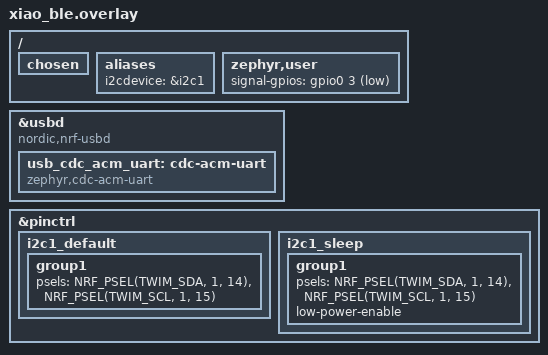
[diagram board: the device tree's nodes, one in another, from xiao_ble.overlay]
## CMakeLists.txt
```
# SPDX-License-Identifier: Apache-2.0

cmake_minimum_required(VERSION 3.20.0)
find_package(Zephyr REQUIRED HINTS $ENV{ZEPHYR_BASE})
project(peripheral)

FILE(GLOB app_sources src/*.c)
target_sources(app PRIVATE ${app_sources})
```

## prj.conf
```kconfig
# Increased stack due to settings API usage
CONFIG_SYSTEM_WORKQUEUE_STACK_SIZE=2048
CONFIG_HEAP_MEM_POOL_SIZE=2048

CONFIG_BOOT_DELAY=5000
CONFIG_BT=y

CONFIG_BT_SMP=y
CONFIG_BT_SIGNING=y
CONFIG_BT_PERIPHERAL=y
CONFIG_BT_DIS=y
CONFIG_BT_ATT_PREPARE_COUNT=5
CONFIG_BT_PRIVACY=y
CONFIG_BT_DEVICE_NAME="PPG Sensor UU"
CONFIG_BT_DEVICE_APPEARANCE=3137
CONFIG_BT_DEVICE_NAME_DYNAMIC=y
CONFIG_BT_DEVICE_NAME_MAX=65


CONFIG_BT_KEYS_OVERWRITE_OLDEST=y
CONFIG_BT_SETTINGS=y
CONFIG_FLASH=y
CONFIG_FLASH_PAGE_LAYOUT=y
CONFIG_FLASH_MAP=y
CONFIG_NVS=y
CONFIG_SETTINGS=y
CONFIG_I2C=y
CONFIG_EVENTS=y
```

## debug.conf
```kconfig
CONFIG_BT_DEBUG_LOG=y
CONFIG_PRINTK=y
CONFIG_ASSERT=y
CONFIG_LOG_DEFAULT_LEVEL=4
CONFIG_LOG=y


#CONFIG_BOOT_DELAY=5000
```

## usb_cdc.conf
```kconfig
CONFIG_STDOUT_CONSOLE=y
CONFIG_SERIAL=y
CONFIG_CONSOLE=y
CONFIG_USB_DEVICE_STACK=y
CONFIG_USB_DEVICE_PRODUCT="ppg_sensor"
CONFIG_UART_CONSOLE=y
CONFIG_UART_LINE_CTRL=y
CONFIG_UART_INTERRUPT_DRIVEN=y
CONFIG_USB_DEVICE_VID=0x0403
CONFIG_USB_DEVICE_PID=0x6001
```

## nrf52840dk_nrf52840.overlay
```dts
/ {
    chosen {
        // zephyr,console = &usb_cdc_acm_uart;
        // zephyr,shell-uart = &usb_cdc_acm_uart;
    };
	aliases {
		i2cdevice = &i2c0;
	};
	zephyr,user {
        signal-gpios = <&gpio0 27 (GPIO_PULL_UP | GPIO_ACTIVE_LOW)>;
    };
};


// zephyr_udc0: &usbd {
// 	compatible = "nordic,nrf-usbd";
// 	status = "okay";

// 	usb_cdc_acm_uart: cdc-acm-uart {
// 		compatible = "zephyr,cdc-acm-uart";
// 	};
// };

&pinctrl {
	i2c0_default: i2c0_default {
		group1 {
			psels = <NRF_PSEL(TWIM_SDA, 0,29)>,
				<NRF_PSEL(TWIM_SCL, 0, 31)>;
		};
	};

	i2c0_sleep: i2c0_sleep {
		group1 {
			psels = <NRF_PSEL(TWIM_SDA, 0, 29)>,
				<NRF_PSEL(TWIM_SCL, 0, 31)>;
			low-power-enable;
		};
	};
};
```

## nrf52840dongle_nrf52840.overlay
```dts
/ {
    chosen {
      //  zephyr,console = &usb_cdc_acm_uart;
      //  zephyr,shell-uart = &usb_cdc_acm_uart;
    };
    zephyr,user {
        signal-gpios = <&gpio0 20 (GPIO_PULL_UP | GPIO_ACTIVE_LOW)>;
    };
};


/* zephyr_udc0: &usbd {
	compatible = "nordic,nrf-usbd";
	status = "okay";

	usb_cdc_acm_uart: cdc-acm-uart {
		compatible = "zephyr,cdc-acm-uart";
	};
}; */



&pinctrl {
	i2c0_default: i2c0_default {
		group1 {
			psels = <NRF_PSEL(TWIM_SDA, 0,29)>,
				<NRF_PSEL(TWIM_SCL, 0, 31)>;
		};
	};

	i2c0_sleep: i2c0_sleep {
		group1 {
			psels = <NRF_PSEL(TWIM_SDA, 0, 29)>,
				<NRF_PSEL(TWIM_SCL, 0, 31)>;
			low-power-enable;
		};
	};
};
```

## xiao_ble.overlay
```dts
/ {
    chosen {
        //zephyr,console = &usb_cdc_acm_uart;
        //zephyr,shell-uart = &usb_cdc_acm_uart;
    };
	aliases {
		i2cdevice = &i2c1;
	};
    zephyr,user {
        signal-gpios = <&gpio0 3 (GPIO_PULL_UP | GPIO_ACTIVE_LOW)>;
    };
};

zephyr_udc0: &usbd {
	compatible = "nordic,nrf-usbd";
	status = "okay";

	usb_cdc_acm_uart: cdc-acm-uart {
		compatible = "zephyr,cdc-acm-uart";
	};
};

&pinctrl {
	i2c1_default: i2c1_default {
		group1 {
			psels = <NRF_PSEL(TWIM_SDA, 1, 14)>,
				<NRF_PSEL(TWIM_SCL, 1, 15)>;
		};
	};

	i2c1_sleep: i2c1_sleep {
		group1 {
			psels = <NRF_PSEL(TWIM_SDA, 1, 14)>,
				<NRF_PSEL(TWIM_SCL, 1, 15)>;
			low-power-enable;
		};
	};
};
```

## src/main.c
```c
/* main.c - Application main entry point */

/*
 * Copyright (c) 2015-2016 Intel Corporation
 *
 * SPDX-License-Identifier: Apache-2.0
 */
#include "main.h"
#include <zephyr/types.h>
#include <stddef.h>
#include <string.h>
#include <errno.h>

#include <zephyr/sys/byteorder.h>
#include <zephyr/kernel.h>

#include <zephyr/logging/log.h>


#include <zephyr/settings/settings.h>

//#include <zephyr/usb/usb_device.h>

//#include <zephyr/drivers/uart.h>


#include <zephyr/bluetooth/bluetooth.h>
#include <zephyr/bluetooth/hci.h>
#include <zephyr/bluetooth/conn.h>
#include <zephyr/bluetooth/uuid.h>
#include <zephyr/bluetooth/gatt.h>
#include <zephyr/drivers/gpio.h>
#include <zephyr/bluetooth/services/hrs.h>


LOG_MODULE_REGISTER(ppgmain);

//#include "cts.h"

//Pulse Oximeter service 0x1822
#define BT_UUID_POS_VAL 0x1822
#define BT_UUID_POS BT_UUID_DECLARE_16(BT_UUID_POS_VAL)

//0x2A5F PLX Continuous Measurement
//#define BT_UUID_PLX_MEASUREMENT_VAL 0x2A5F
//#define BT_UUID_PLX_MEASUREMENT BT_UUID_DECLARE_16(BT_UUID_PLX_MEASUREMENT_VAL)

//Fingertip Pulse Oximeter 0x0C41
#define BT_UUID_FINGERTIP_PO_MEASUREMENT_VAL 0x0C41
#define BT_UUID_FINGERTIP_PO_MEASUREMENT BT_UUID_DECLARE_16(BT_UUID_FINGERTIP_PO_MEASUREMENT_VAL)


#define ZEPHYR_USER_NODE DT_PATH(zephyr_user)

volatile bool notify_enable = 0;

K_EVENT_DEFINE(notify_event);

static void vnd_ccc_cfg_changed(const struct bt_gatt_attr *attr, uint16_t value)
{
	ARG_UNUSED(attr);
	notify_enable = (value == BT_GATT_CCC_NOTIFY);
	LOG_INF("value %i", value);
	k_event_post(&notify_event, (value ? evt_powerup : evt_powerdown));
}

BT_GATT_SERVICE_DEFINE(ppg_svc,
	BT_GATT_PRIMARY_SERVICE(BT_UUID_POS),	
		BT_GATT_CHARACTERISTIC(BT_UUID_FINGERTIP_PO_MEASUREMENT,
					BT_GATT_CHRC_READ | BT_GATT_CHRC_WRITE |
			        BT_GATT_CHRC_NOTIFY, 
					BT_GATT_PERM_READ | BT_GATT_PERM_WRITE, NULL, NULL, NULL),
			BT_GATT_CCC(vnd_ccc_cfg_changed,
					BT_GATT_PERM_READ | BT_GATT_PERM_WRITE),				
);


static const struct bt_data ad[] = {
	BT_DATA_BYTES(BT_DATA_FLAGS, (BT_LE_AD_GENERAL | BT_LE_AD_NO_BREDR)),
	BT_DATA_BYTES(BT_DATA_UUID16_ALL,
			   BT_UUID_16_ENCODE(BT_UUID_POS_VAL),
		      	BT_UUID_16_ENCODE(BT_UUID_BAS_VAL),
			  ),	
};

K_SEM_DEFINE(sem_initialized_max30102, 0, 1);
K_SEM_DEFINE(sem_interruptmax30102, 0, 1);
K_FIFO_DEFINE(ppg_items);

static struct gpio_callback interrupt_max30102;
static const struct gpio_dt_spec signal = GPIO_DT_SPEC_GET(ZEPHYR_USER_NODE, signal_gpios);





void mtu_updated(struct bt_conn *conn, uint16_t tx, uint16_t rx)
{
	LOG_DBG("Updated MTU: TX: %d RX: %d bytes\n", tx, rx);
}

static struct bt_gatt_cb gatt_callbacks = {
	.att_mtu_updated = mtu_updated
};

static void connected(struct bt_conn *conn, uint8_t err)
{
	if (err) {
		LOG_ERR("Connection failed (err 0x%02x)\n", err);
	} else {
		LOG_INF("Connected\n");		
	}
}

static void disconnected(struct bt_conn *conn, uint8_t reason)
{
	LOG_INF("Disconnected (reason 0x%02x)\n", reason);	
}

BT_CONN_CB_DEFINE(conn_callbacks) = {
	.connected = connected,
	.disconnected = disconnected,	
};


static void bt_ready(void)
{
	int err;

	LOG_DBG("Bluetooth initialized\n");
	

	if (IS_ENABLED(CONFIG_SETTINGS)) {
		settings_load();
	}

	err = bt_le_adv_start(BT_LE_ADV_CONN_NAME, ad, ARRAY_SIZE(ad), NULL, 0);
	if (err) {
		LOG_ERR("Advertising failed to start (err %d)\n", err);
		return;
	}

	LOG_DBG("Advertising successfully started\n");
}

static void auth_passkey_display(struct bt_conn *conn, unsigned int passkey)
{
	char addr[BT_ADDR_LE_STR_LEN];

	bt_addr_le_to_str(bt_conn_get_dst(conn), addr, sizeof(addr));

	printk("Passkey for %s: %06u\n", addr, passkey);
}

static void auth_cancel(struct bt_conn *conn)
{
	char addr[BT_ADDR_LE_STR_LEN];

	bt_addr_le_to_str(bt_conn_get_dst(conn), addr, sizeof(addr));

	LOG_INF("Pairing cancelled: %s\n", addr);
}

static struct bt_conn_auth_cb auth_cb_display = {
	.passkey_display = auth_passkey_display,
	.passkey_entry = NULL,
	.cancel = auth_cancel,
	
};


void max30102isr(const struct device *dev, struct gpio_callback *cb, uint32_t pins) {	
	k_sem_give(&sem_interruptmax30102);			
}

void attachinterrupt(void) {
	
	__ASSERT(device_is_ready(signal.port), "custom device not ready");
	gpio_pin_configure_dt(&signal, GPIO_INPUT);
	gpio_pin_interrupt_configure_dt(&signal, GPIO_INT_EDGE_TO_ACTIVE);
	gpio_init_callback(&interrupt_max30102, max30102isr, BIT(signal.pin));
	gpio_add_callback(signal.port, &interrupt_max30102);	
	LOG_INF("attached");
}



void main(void)
{


// #if DT_NODE_HAS_COMPAT(DT_CHOSEN(zephyr_shell_uart), zephyr_cdc_acm_uart)
// 	const struct device *dev;
// 	uint32_t dtr = 0;

// 	dev = DEVICE_DT_GET(DT_CHOSEN(zephyr_shell_uart));
// 	if (!device_is_ready(dev) || usb_enable(NULL)) {
// 		return;
// 	}

// 	while (!dtr) {
// 		uart_line_ctrl_get(dev, UART_LINE_CTRL_DTR, &dtr);
// 		k_sleep(K_MSEC(100));
// 	}
// #endif	



	struct bt_gatt_attr *vnd_ind_attr;
	char str[BT_UUID_STR_LEN];
	int err;
	LOG_INF("enabling bt");
	err = bt_enable(NULL);
	if (err) {
		LOG_ERR("Bluetooth init failed (err %d)\n", err);
		return;
	}
	LOG_INF("bt enabled");

	bt_ready();

	bt_gatt_cb_register(&gatt_callbacks);
	bt_conn_auth_cb_register(&auth_cb_display);
	
	static struct bt_uuid_16 vnd_enc_uuid = BT_UUID_INIT_16(BT_UUID_FINGERTIP_PO_MEASUREMENT_VAL);
	vnd_ind_attr = bt_gatt_find_by_uuid(ppg_svc.attrs, ppg_svc.attr_count,
					    &vnd_enc_uuid.uuid);
						

	//bt_uuid_to_str(&vnd_enc_uuid.uuid, str, sizeof(str));
	bt_uuid_to_str(BT_UUID_POS, str, sizeof(str));
	LOG_DBG("Indicate VND attr %p (UUID %s)\n", vnd_ind_attr, str);	
	
	if(max30102_init()) {
		LOG_ERR("could not initialize");
		k_sleep(K_FOREVER);		
	}		
	attachinterrupt();	
	uint8_t max_read_state = max30102_interrupt_state(); //clear interrupt;
	LOG_DBG("max initialized, read state:%i", max_read_state);	
	k_sem_give(&sem_initialized_max30102);			
	shutdown();


	fifo_item_t *queued;
	for(;;) {
		
		queued = k_fifo_get(&ppg_items, K_FOREVER);	
		uint32_t test = 42;
		if (notify_enable) {			
			
			err = bt_gatt_notify(NULL, vnd_ind_attr, &test, sizeof(uint32_t));
			if (err) {
				LOG_ERR("Notify error: %d", err);
			} else {
				LOG_INF("Send notify ir %i", queued->item->ir);	
			}		
		}		
		k_free(queued->item);
	}
}


void max30102read(void) {	
	k_sem_take(&sem_initialized_max30102, K_FOREVER);
	
	uint8_t amount_samples;
	uint8_t isrstate;
	ppg_item_t buffer[32]; //maximum amount for ic
	while (1) {		
		k_sem_take(&sem_interruptmax30102, K_FOREVER);
		LOG_DBG("sem_interrupt_received");
		isrstate = max30102_interrupt_state();
		if (isrstate != 0b10000000) {
			LOG_WRN("unexpected max30102int: %d", isrstate);			
			continue;
		} 
		amount_samples = GetSamplesAvailable();		
		
		max30102data(buffer, amount_samples);
		
		for (int i = 0; i < amount_samples; i++)
		{						
			fifo_item_t toqueue; // = k_malloc(sizeof(fifo_item_t));			
			toqueue.item = k_malloc(sizeof(ppg_item_t));
			memcpy(toqueue.item, &buffer[i], sizeof(ppg_item_t));
			LOG_DBG("queued ir %i:", toqueue.item->ir);
			k_fifo_put(&ppg_items, &toqueue);
		} 			
	}
}
void power_thread(void) {
	for(;;) {
		uint32_t events;
		events = k_event_wait(&notify_event, (evt_powerup | evt_powerdown), true, K_FOREVER);
		LOG_DBG("received %i", events);
		if(events == evt_powerdown) {
			shutdown();		
		} else if(events == evt_powerup) {
			powerup();
		}
	}
}

K_THREAD_DEFINE(notify_read_id, 1024, power_thread, NULL, NULL,
		NULL, 8, 0, 0);

K_THREAD_DEFINE(max30102_read_thread_id, 1024, max30102read, NULL, NULL,
		NULL, 7, 0, 0);
```

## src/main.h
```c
#include <stdio.h>
#include <zephyr/kernel.h>
#include "max30102.h"

typedef struct { 
    void *fifo_reserved;   /* 1st word reserved for use by FIFO */    
	ppg_item_t * item;
} fifo_item_t;

enum powerevents {
	evt_powerup = 1,
	evt_powerdown = 2,
};
```

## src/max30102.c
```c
#include <zephyr/logging/log.h>
#include <stdio.h>
#include <zephyr/kernel.h>
#include "max30102.h"
#include <zephyr/drivers/gpio.h>
#include <zephyr/drivers/i2c.h>

#define register_count 9
#define led_channels 1

const struct device *i2c;


max30102_config max30102cfg = {
// 	.i2c_label = DT_INST_PROP(0, label),
 	.i2c_addr = 0x57// DT_INST_REG_ADDR(0),
};


LOG_MODULE_REGISTER(MAX30102);

int GetSamplesAvailable()
{
	uint8_t fifo_wr_ptr;
	uint8_t fifo_rd_ptr;
	int samples_avalable = 0;

	int wr = i2c_reg_read_byte(i2c, max30102cfg.i2c_addr, 0x04, &fifo_wr_ptr);
	int rd = i2c_reg_read_byte(i2c, max30102cfg.i2c_addr, 0x06, &fifo_rd_ptr);
	if(wr || rd) {
		LOG_ERR("max30102 read or write pointer error");
		return 0;
	}

	if (fifo_wr_ptr != fifo_rd_ptr)
	{
		samples_avalable = fifo_wr_ptr - fifo_rd_ptr;
		if (samples_avalable < 0) {
			samples_avalable += 32; // wrap condition>		
		}
	}	
	return samples_avalable;
}

float temperature(void)
{
	uint8_t temperature;
	uint8_t fraction;
	i2c_reg_read_byte(i2c, max30102cfg.i2c_addr, 0x1F, &temperature);
	i2c_reg_read_byte(i2c, max30102cfg.i2c_addr, 0x20, &fraction);
	if (temperature > 0x7F)
	{
		temperature = -0xFF + (temperature - 1);
	}
	// enable temperature
	i2c_reg_write_byte(i2c, max30102cfg.i2c_addr, 0x21, 1);
	return (float)temperature + fraction * 0.0625;
}


int fetch_max30102(uint32_t * samplebuffer, int samplesToTake)
{
	if (samplesToTake == 0) return 0;	
	
	uint32_t fifo_data;
	int num_bytes = 3 * led_channels * samplesToTake; //2 channels, 3 bytes each
	uint8_t buffer[num_bytes];

	/* Read all the active channels for all samples */		 
	if (i2c_burst_read(i2c, max30102cfg.i2c_addr, 0x07, buffer, num_bytes))
	{
		LOG_ERR("could not read sample");
		return 1;
	}
	
	for (uint32_t y = 0; y < (samplesToTake * led_channels); y++)
	{				
		/* Each channel sample is 18-bits */
		fifo_data = (buffer[y*3] << 16) | (buffer[y*3 + 1] << 8) |
					(buffer[y*3 + 2]);
		fifo_data &= MAX30102_FIFO_DATA_MASK;

		samplebuffer[y] = fifo_data;
	}

	return 0;
}

int max30102data(ppg_item_t * ppg_items, int samplesToTake) {
	int buffersize = samplesToTake * led_channels;
	uint32_t buffer[buffersize]; //two led colors
	if(fetch_max30102(buffer, samplesToTake)){
		return 1;
	}
	unsigned int pic = 0; //ppg item count
	for (size_t i = 0; i < buffersize; i+=led_channels)
	{				
		ppg_items[pic].ir = buffer[i];
#if(led_channels > 1)
		ppg_items[pic].red = buffer[i+1];	
#else
		ppg_items[pic].red = 0;	
#endif
		pic++;
	}
	return 0;
}

uint8_t max30102_interrupt_state() {
	uint8_t status;
	i2c_reg_read_byte(i2c, max30102cfg.i2c_addr, 0x00, &status);
	return status;
}

int safewriteconfig(uint8_t reg, uint8_t value) {
	if (i2c_reg_write_byte(i2c, max30102cfg.i2c_addr, reg,value))
	{
		LOG_ERR("couldn't write to 0x%02x", reg);
		return -EIO;
	}
	return 0;
}

int shutdown() {
	LOG_DBG("shutdown now");
	return safewriteconfig(0x09, 0b10000010);
}

int powerup() {
	LOG_DBG("powered on");
	return safewriteconfig(0x09, 0b00000010);
}

int max30102_init()
{
	uint8_t part_id;
	uint8_t mode_cfg;

	/* Get the I2C device */	
	i2c = DEVICE_DT_GET(DT_ALIAS(i2cdevice));
	//i2c = DEVICE_DT_GET(DT_NODELABEL(i2c1));
	__ASSERT(device_is_ready(i2c), "max30102 device not ready");		

	/* Check the part id to make sure this is MAX30102 */
	if (i2c_reg_read_byte(i2c, max30102cfg.i2c_addr,
						  MAX30102_REG_PART_ID, &part_id))
	{
		LOG_ERR("Could not get Part ID");
		return -EIO;
	}
	if (part_id != MAX30102_PART_ID)
	{
		LOG_ERR("Got Part ID 0x%02x, expected 0x%02x",
				part_id, MAX30102_PART_ID);
		return -EIO;
	}
	else
	{
		LOG_INF("Got Part ID 0x%02x as expected", part_id);
	}

	/* Reset the sensor */
	if (i2c_reg_write_byte(i2c, max30102cfg.i2c_addr,
						   MAX30102_REG_MODE_CFG,
						   MAX30102_MODE_CFG_RESET_MASK))
	{
		return -EIO;
	}

	/* Wait for reset to be cleared */
	do
	{
		if (i2c_reg_read_byte(i2c, max30102cfg.i2c_addr,
							  MAX30102_REG_MODE_CFG, &mode_cfg))
		{
			LOG_ERR("Could read mode cfg after reset");
			return -EIO;
		}
	} while (mode_cfg & MAX30102_MODE_CFG_RESET_MASK);
	
	uint8_t regsettings[register_count][2] = {
			//Interrupt Enable
			{0x02, 0b10000000},
			//DIE_TEMP_RDY_EN = false
			{0x03, 0b00000000},
			//FIFO config - average, yes rollover, fifo almost full @ 4 left	
			{0x08, 0b11111111},
			// mode configuration
			{0x09, 0b00000010},
			//Sample Rate Control
			{0x0A, 0b01110111},
			//LED pulse amplitude 
			{0x0C, 0x7f},  	//red
			{0x0D, 0x7f},	//ir
			//multi-LED mode control 
			{0x11, 0b00000010},
			{0x12, 0b00000000}
		};		
	
	for (size_t i = 0; i < register_count; i++)
	{		
		if(safewriteconfig(regsettings[i][0], regsettings[i][1])) {
			return -EIO;
		}
	}

	return 0;
}
```

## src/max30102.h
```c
#include <stdio.h>
#include <zephyr/types.h>

#define MAX30102_REG_INT_STS1		0x00
#define MAX30102_REG_INT_STS2		0x01
#define MAX30102_REG_INT_EN1		0x02
#define MAX30102_REG_INT_EN2		0x03
#define MAX30102_REG_FIFO_WR		0x04
#define MAX30102_REG_FIFO_OVF		0x05
#define MAX30102_REG_FIFO_RD		0x06
#define MAX30102_REG_FIFO_DATA		0x07
#define MAX30102_REG_FIFO_CFG		0x08
#define MAX30102_REG_MODE_CFG		0x09
#define MAX30102_REG_SPO2_CFG		0x0a

#define MAX30102_REG_PILOT_PA		0x10

#define MAX30102_REG_TINT		0x1f
#define MAX30102_REG_TFRAC		0x20
#define MAX30102_REG_TEMP_CFG		0x21
#define MAX30102_REG_PROX_INT		0x30
#define MAX30102_REG_REV_ID		0xfe
#define MAX30102_REG_PART_ID		0xff

#define MAX30102_INT_PPG_MASK		(1 << 6)

#define MAX30102_FIFO_CFG_SMP_AVE_SHIFT		5
#define MAX30102_FIFO_CFG_FIFO_FULL_SHIFT	0
#define MAX30102_FIFO_CFG_ROLLOVER_EN_MASK	(1 << 4)

#define MAX30102_MODE_CFG_SHDN_MASK	(1 << 7)
#define MAX30102_MODE_CFG_RESET_MASK	(1 << 6)

#define MAX30102_SPO2_ADC_RGE_SHIFT	5
#define MAX30102_SPO2_SR_SHIFT		2
#define MAX30102_PART_ID		0x15

#define MAX30102_BYTES_PER_CHANNEL	3
#define MAX30102_MAX_NUM_CHANNELS	2
#define MAX30102_MAX_BYTES_PER_SAMPLE	(MAX30102_MAX_NUM_CHANNELS * MAX30102_BYTES_PER_CHANNEL)

#define MAX30102_SLOT_LED_MASK		0x03

#define MAX30102_FIFO_DATA_BITS		18
#define MAX30102_FIFO_DATA_MASK		((1 << MAX30102_FIFO_DATA_BITS) - 1)



typedef struct {
	uint32_t ir;
	uint32_t red;
} ppg_item_t;

enum max30102_mode {
	MAX30102_MODE_HEART_RATE	= 2,
	MAX30102_MODE_SPO2		= 3,
	MAX30102_MODE_MULTI_LED		= 7,
};

enum max30102_led_channel {
	MAX30102_LED_CHANNEL_RED	= 0,
	MAX30102_LED_CHANNEL_IR,
};

enum max30102_pw {
	MAX30102_PW_15BITS		= 0,
	MAX30102_PW_16BITS,
	MAX30102_PW_17BITS,
	MAX30102_PW_18BITS,
};

typedef struct {	
	const char *i2c_label;
	uint16_t i2c_addr;			
} max30102_config;

int shutdown();
int powerup();
float temperature();
int max30102_init();
int GetSamplesAvailable();
int max30102data(ppg_item_t * ppg_items, int samplesToTake);
uint8_t max30102_interrupt_state();
```
